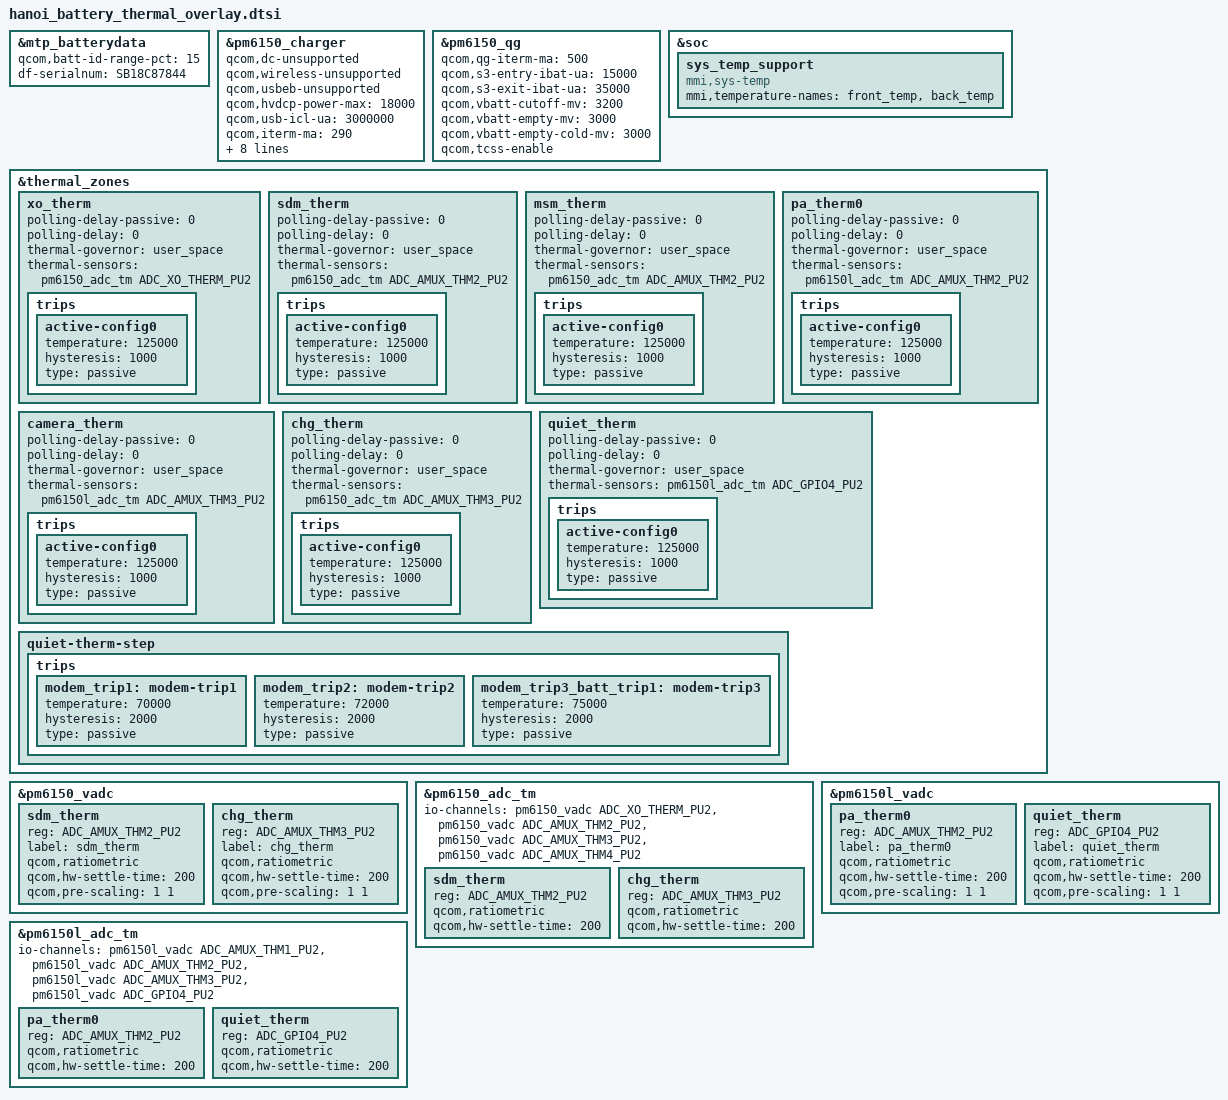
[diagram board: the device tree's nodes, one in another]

&mtp_batterydata {
       qcom,batt-id-range-pct = <15>;
       df-serialnum = "SB18C87844";
       #include "qg-batterydata-mc50-ATL-4V45_6000mah.dtsi"
       #include "qg-batterydata-mc50-SUNWODA-4V45_6000mah.dtsi"
};

&pm6150_charger {
       /delete-property/qcom,support-mods;
       qcom,dc-unsupported;
       qcom,wireless-unsupported;
       qcom,usbeb-unsupported;
       qcom,hvdcp-power-max = <18000>;
       qcom,usb-icl-ua = <3000000>;
       qcom,iterm-ma = <290>;
       qcom,upper-limit-capacity = <65>;
       qcom,lower-limit-capacity = <60>;
       qcom,fv-max-uv = <4450000>;
       qcom,thermal-mitigation =  <3600>,
                                  <3000>,
                                  <2500>,
                                  <2000>,
                                  <1500>,
                                  <1200>,
                                  <900>,
                                  <700>,
                                  <500>;
       qcom,mmi-temp-zones =   <0 4200 1164 0>,
                               <10 4200 3000 1164>,
                               <15 0 3000 3000>,
                               <45 0 3600 3600>,
                               <60 4200 3000 0>;
};

&pm6150_qg {
        qcom,qg-iterm-ma = <500>;
        qcom,s3-entry-ibat-ua = <15000>;
        qcom,s3-exit-ibat-ua = <35000>;
        qcom,vbatt-cutoff-mv = <3200>;
        qcom,vbatt-empty-mv = <3000>;
        qcom,vbatt-empty-cold-mv = <3000>;
	qcom,tcss-enable;
};

&soc {
        sys_temp_support {
                compatible = "mmi,sys-temp";
                mmi,temperature-names = "front_temp",
                        "back_temp";
                status = "ok";
        };

};

&thermal_zones {
        xo_therm {
                polling-delay-passive = <0>;
                polling-delay = <0>;
                thermal-governor = "user_space";
                thermal-sensors = <&pm6150_adc_tm ADC_XO_THERM_PU2>;
                trips {
                        active-config0 {
                                temperature = <125000>;
                                hysteresis = <1000>;
                                type = "passive";
                        };
                };
        };

        sdm_therm {
                polling-delay-passive = <0>;
                polling-delay = <0>;
                thermal-governor = "user_space";
                thermal-sensors = <&pm6150_adc_tm ADC_AMUX_THM2_PU2>;
                trips {
                        active-config0 {
                                temperature = <125000>;
                                hysteresis = <1000>;
                                type = "passive";
                        };
                };
        };

        msm_therm {
                polling-delay-passive = <0>;
                polling-delay = <0>;
                thermal-governor = "user_space";
                thermal-sensors = <&pm6150_adc_tm ADC_AMUX_THM2_PU2>;
                trips {
                        active-config0 {
                                temperature = <125000>;
                                hysteresis = <1000>;
                                type = "passive";
                        };
                };
        };

        pa_therm0 {
                polling-delay-passive = <0>;
                polling-delay = <0>;
                thermal-governor = "user_space";
                thermal-sensors = <&pm6150l_adc_tm ADC_AMUX_THM2_PU2>;
                trips {
                        active-config0 {
                                temperature = <125000>;
                                hysteresis = <1000>;
                                type = "passive";
                        };
                };
        };

        /delete-node/ camera-ftherm-adc;
        camera_therm {
                polling-delay-passive = <0>;
                polling-delay = <0>;
                thermal-governor = "user_space";
                thermal-sensors = <&pm6150l_adc_tm ADC_AMUX_THM3_PU2>;
                trips {
                        active-config0 {
                                temperature = <125000>;
                                hysteresis = <1000>;
                                type = "passive";
                        };
                };
        };

        chg_therm {
                polling-delay-passive = <0>;
                polling-delay = <0>;
                thermal-governor = "user_space";
                thermal-sensors = <&pm6150_adc_tm ADC_AMUX_THM3_PU2>;
                trips {
                        active-config0 {
                                temperature = <125000>;
                                hysteresis = <1000>;
                                type = "passive";
                        };
                };
        };

        quiet_therm {
                polling-delay-passive = <0>;
                polling-delay = <0>;
                thermal-governor = "user_space";
                thermal-sensors = <&pm6150l_adc_tm ADC_GPIO4_PU2>;
                trips {
                        active-config0 {
                                temperature = <125000>;
                                hysteresis = <1000>;
                                type = "passive";
                        };
                };
        };
        quiet-therm-step {
                trips {
                        modem_trip1: modem-trip1 {
                                temperature = <70000>;
                                hysteresis = <2000>;
                                type = "passive";
                        };
                        modem_trip2: modem-trip2 {
                                temperature = <72000>;
                                hysteresis = <2000>;
                                type = "passive";
                        };
                        modem_trip3_batt_trip1: modem-trip3 {
                                temperature = <75000>;
                                hysteresis = <2000>;
                                type = "passive";
                        };
                };
        };
};

&pm6150_vadc {
        sdm_therm {
                reg = <ADC_AMUX_THM2_PU2>;
                label = "sdm_therm";
                qcom,ratiometric;
                qcom,hw-settle-time = <200>;
                qcom,pre-scaling = <1 1>;
        };

        chg_therm {
                reg = <ADC_AMUX_THM3_PU2>;
                label = "chg_therm";
                qcom,ratiometric;
                qcom,hw-settle-time = <200>;
                qcom,pre-scaling = <1 1>;
        };
};

&pm6150_adc_tm {
        io-channels = <&pm6150_vadc ADC_XO_THERM_PU2>,
                        <&pm6150_vadc ADC_AMUX_THM2_PU2>,
                        <&pm6150_vadc ADC_AMUX_THM3_PU2>,
                        <&pm6150_vadc ADC_AMUX_THM4_PU2>;
        sdm_therm {
                reg = <ADC_AMUX_THM2_PU2>;
                qcom,ratiometric;
                qcom,hw-settle-time = <200>;
        };

        chg_therm {
                reg = <ADC_AMUX_THM3_PU2>;
                qcom,ratiometric;
                qcom,hw-settle-time = <200>;
        };
};

&pm6150l_vadc {
        pa_therm0 {
                reg = <ADC_AMUX_THM2_PU2>;
                label = "pa_therm0";
                qcom,ratiometric;
                qcom,hw-settle-time = <200>;
                qcom,pre-scaling = <1 1>;
        };

        quiet_therm {
                reg = <ADC_GPIO4_PU2>;
                label = "quiet_therm";
                qcom,ratiometric;
                qcom,hw-settle-time = <200>;
                qcom,pre-scaling = <1 1>;
        };
};

&pm6150l_adc_tm {
        io-channels = <&pm6150l_vadc ADC_AMUX_THM1_PU2>,
                        <&pm6150l_vadc ADC_AMUX_THM2_PU2>,
                        <&pm6150l_vadc ADC_AMUX_THM3_PU2>,
                        <&pm6150l_vadc ADC_GPIO4_PU2>;

        pa_therm0 {
                reg = <ADC_AMUX_THM2_PU2>;
                qcom,ratiometric;
                qcom,hw-settle-time = <200>;
        };

        quiet_therm {
                reg = <ADC_GPIO4_PU2>;
                qcom,ratiometric;
                qcom,hw-settle-time = <200>;
        };
};

